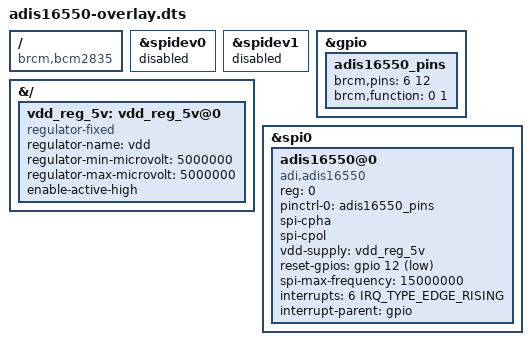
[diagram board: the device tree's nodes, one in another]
// SPDX-License-Identifier: GPL-2.0
/dts-v1/;
/plugin/;

#include <dt-bindings/interrupt-controller/irq.h>
#include <dt-bindings/gpio/gpio.h>

/ {
	compatible = "brcm,bcm2835";
};

&spidev0 {
	status = "disabled";
};

&spidev1{
	status = "disabled";
};

&gpio{
	adis16550_pins: adis16550_pins {
		brcm,pins = <6 12>;
		brcm,function = <0 1>;
	};
};

&{/} {
	vdd_reg_5v: vdd_reg_5v@0 {
		compatible = "regulator-fixed";
		regulator-name = "vdd";
		regulator-min-microvolt = <5000000>;
		regulator-max-microvolt = <5000000>;
		enable-active-high;
	};
};

&spi0{
	#address-cells = <1>;
	#size-cells = <0>;
	status = "okay";

	adis16550@0 {
		compatible = "adi,adis16550";
		reg = <0>;
		pinctrl-names = "default";
		pinctrl-0 = <&adis16550_pins>;
		spi-cpha;
		spi-cpol;
		vdd-supply = <&vdd_reg_5v>;
		reset-gpios = <&gpio 12 GPIO_ACTIVE_LOW>;
		spi-max-frequency = <15000000>;
		interrupts = <6 IRQ_TYPE_EDGE_RISING>;
		interrupt-parent = <&gpio>;
	};
};
